# SLIMBUS1_DSP register map
Vendor: Texas Instruments
Peripheral module from a debugger description file (folder omap5430_ES2_PUBLIC).
Registers are 32-bit, access per field, reset 0x0 unless marked. A register's access mark holds for its fields unless they carry their own. Offsets are as the file gives them; lines under a group give offsets from that group; [hi:lo] are bit positions; {n}, {i} and the like mark numbered series; 'fields as' and 'values as' point back to an identical list; <NAME> marks a mode.

## SLIMBUS1_DSP
0x00 SLIMBUS_CMP_REVISION ro reset not defined — IP Revision Identifier Used by software to track features, bugs, and compatibility
  [31:0] REVISION — Revision Number
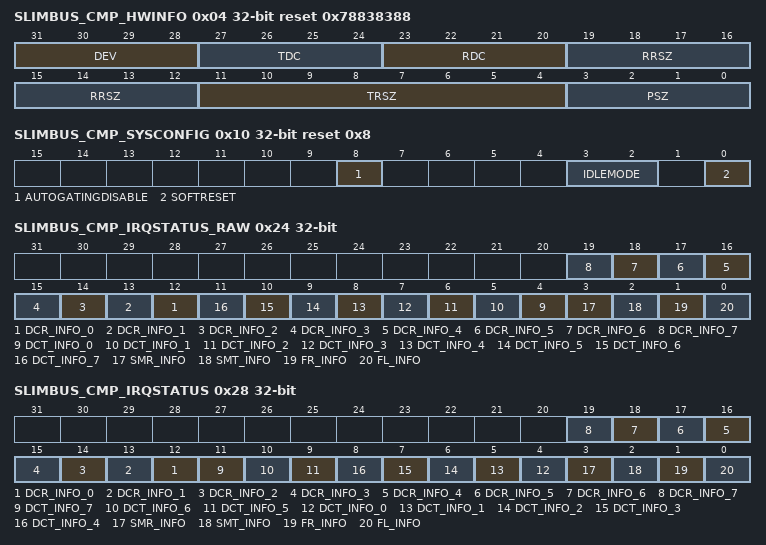
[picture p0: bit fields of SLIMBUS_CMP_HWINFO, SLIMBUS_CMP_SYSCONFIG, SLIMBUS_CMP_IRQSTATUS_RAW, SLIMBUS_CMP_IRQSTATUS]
0x04 SLIMBUS_CMP_HWINFO ro reset 0x78838388 — Those read-only, hardcoded fields display the values of the eponymous hardware configuration
  [31:28] DEV — Device count: number of devices supported by the component, most notably through the automatically reception of the messages addressed to them. Sets the number of instances of the 'DEV_XYZ' registers.
  [27:24] TDC — Transmit Data agent Count: Number of transmit hardware data agents (FIFO and associated logic) Sets the number of instances of the 'DCT_XYZ' registers.
  [23:20] RDC — Receive Data agent Count: Number of receive hardware data agents (FIFO and associated logic) Sets the number of instances of the 'DCR_XYZ' registers.
  [19:12] RRSZ — Size of receive FIFO RAM, in 32-bit words. RX message FIFO and all RX data FIFOs map to that shared RAM.
  [11:4] TRSZ — Size of transmit FIFO RAM, in 32-bit words. TX message FIFO and all TX data FIFOs map to that shared RAM.
  [3:0] PSZ — Size of (both TX and RX) FIFO segment word pointers, in bits. Determines the maximum number of (variable-sized) segment words a data agent FIFO can contain. Sets the width of FIFO control and status fields: size, threshold, level.
0x10 SLIMBUS_CMP_SYSCONFIG reset 0x8 — This register allows controlling various parameters of the interconnect interface
  [8] AUTOGATINGDISABLE rw — Control of the internal clock autogating for safety / debug only. No impact on module functionality, only on dynamic power.
    0=Internal clocks are gated off when unused, power is optimized; 1=Internal clocks are free-running, maximum dynamic power
  [3:2] IDLEMODE rw — Configuration of the local target state management mode. By definition, target can handle read/write transaction as long as it is out of IDLE state.
    0=IP_0 (Force-idle mode: local target's idle state follows (acknowledges) the system's idle requests unconditionally, that is, regardless of the IP module's internal requirements. Backup mode, for debug only.); 1=No-idle mode: local target never enters idle state. Backup mode, for debug only.; 2=IP_IP_(IRQ-_2 (Smart-idle mode: local target's idle state eventually follows (acknowledges) the system's idle requests, depending on the IP module's internal requirements. IP module shall not generate (IRQ- or DMA-request-related) wakeup events.); 3=IP_IP_(IRQ-_3 (Smart-idle wakeup-capable mode: local target's idle state eventually follows (acknowledges) the system's idle requests, depending on the IP module's internal requirements. IP module may generate (IRQ- or DMA-request-related) wakeup events when in idle state.)
  [0] SOFTRESET rw — Software reset. (Optional)
    0=No_action; 1=Initiate_software_reset; 1=Reset_(software_or_other)_ongoing; 0=Reset_done,_no_pending_action
0x24 SLIMBUS_CMP_IRQSTATUS_RAW access not given — Component (that is, main) interrupt request status. Check the corresponding secondary status register. Raw status is set even if event is not enabled. Write 1 to set the (raw) status, mostly for debug.
  [all] fields
    0=No_action; 1=Trigger_IRQ_event_by_software; 1=IRQ_event_pending; 0=No_event_pending
  [n+12] DCR_INFO_{n} (n=0..7) — IRQ status for RX Data agent {n} (access RW W1toSet)
  [n+4] DCT_INFO_{n} (n=0..7) — IRQ status for TX Data agent {n} (access RW W1toSet)
  [3] SMR_INFO — IRQ status for message receive (access RW W1toSet)
  [2] SMT_INFO — IRQ status for message transmit (access RW W1toSet)
  [1] FR_INFO — IRQ status for Framer device, when active (access RW W1toSet)
  [0] FL_INFO — IRQ status for Frame Layer (access RW W1toSet)
0x28 SLIMBUS_CMP_IRQSTATUS access not given — Component (that is, main) interrupt request status. Check the corresponding secondary status register. Enabled status isn't set unless event is enabled. Write 1 to clear the status after interrupt has been serviced (raw status gets cleared, that is, even if not enabled).
  [all] fields
    0=No_action; 1=Clear_pending_event,_if_any; 1=IRQ_event_pending; 0=No_event_pending
  [n+12] DCR_INFO_{n} (n=0..7) — IRQ status for RX Data agent {n} (access RW W1toClr)
  [11] DCT_INFO_7 — IRQ status for TX Data agent 7 (access RW W1toClr)
  [10] DCT_INFO_6 — IRQ status for TX Data agent 6 (access RW W1toClr)
  [9] DCT_INFO_5 — IRQ status for TX Data agent 5. (access RW W1toClr)
  [n+4] DCT_INFO_{n} (n=0..4) — IRQ status for TX Data agent {n} (access RW W1toClr)
  [3] SMR_INFO — IRQ status for message receive (access RW W1toClr)
  [2] SMT_INFO — IRQ status for message transmit (access RW W1toClr)
  [1] FR_INFO — IRQ status for Framer device, when active (access RW W1toClr)
  [0] FL_INFO — IRQ status for Frame Layer (access RW W1toClr)
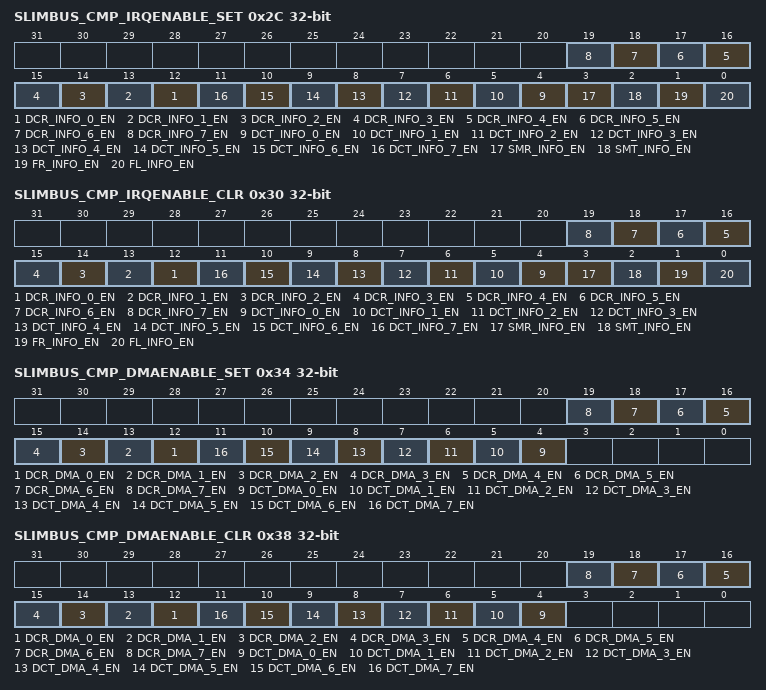
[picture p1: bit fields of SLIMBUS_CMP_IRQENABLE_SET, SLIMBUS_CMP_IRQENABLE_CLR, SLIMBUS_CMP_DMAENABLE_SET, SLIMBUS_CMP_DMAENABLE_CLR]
0x2C SLIMBUS_CMP_IRQENABLE_SET access not given — Component (that is, main) interrupt request enable Write 1 to set (enable interrupt). Readout equal to corresponding _CLR register.
  [all] fields
    0=No_action; 1=Set_IRQ_enable_(that_is,_enable_event); 1=IRQ_event_is_enabled; 0=IRQ_event_is_disabled
  [n+12] DCR_INFO_{n}_EN (n=0..7) — IRQ enable for RX Data agent {n} (access RW W1toSet)
  [n+4] DCT_INFO_{n}_EN (n=0..7) — IRQ enable for TX Data agent {n} (access RW W1toSet)
  [3] SMR_INFO_EN — IRQ enable for message receive (access RW W1toSet)
  [2] SMT_INFO_EN — IRQ enable for message transmit (access RW W1toSet)
  [1] FR_INFO_EN — IRQ enable for Framer device, when active (access RW W1toSet)
  [0] FL_INFO_EN — IRQ enable for Frame Layer (access RW W1toSet)
0x30 SLIMBUS_CMP_IRQENABLE_CLR access not given — Component (that is, main) interrupt request enable Write 1 to clear (disable interrupt). Readout equal to corresponding _SET register.
  [all] fields
    0=No_action; 1=IRQ_1 (Clear IRQ enable (that is, disable event)); 1=IRQ_event_is_enabled; 0=IRQ_event_is_disabled
  [n+12] DCR_INFO_{n}_EN (n=0..7) — IRQ enable for RX data agent {n} (access RW W1toClr)
  [n+4] DCT_INFO_{n}_EN (n=0..7) — IRQ enable for TX Data agent {n} (access RW W1toClr)
  [3] SMR_INFO_EN — IRQ enable for message receive (access RW W1toClr)
  [2] SMT_INFO_EN — IRQ enable for message transmit (access RW W1toClr)
  [1] FR_INFO_EN — IRQ enable for Framer device, when active (access RW W1toClr)
  [0] FL_INFO_EN — IRQ enable for Frame Layer (access RW W1toClr)
0x34 SLIMBUS_CMP_DMAENABLE_SET access not given — Components DMA enable (1 bit per DMA-capable channel) Write 1 to set (enable DMA). Readout equal to corresponding _CLR register.
  [all] fields
    0=No_action; 1=DMA_1 (Set DMA enable (that is, enable channel)); 1=DMA_channel_is_enabled; 0=DMA_chanel_is_disabled
  [n+12] DCR_DMA_{n}_EN (n=0..7) — DMA enable for RX Data agent {n} (access RW W1toSet.)
  [n+4] DCT_DMA_{n}_EN (n=0..7) — DMA enable for TX Data agent {n} (access RW W1toSet)
0x38 SLIMBUS_CMP_DMAENABLE_CLR access not given — Components DMA enable (1 bit per DMA-capable channel) Write 1 to clear (disable DMA). Readout equal to corresponding _SET register.
  [all] fields
    0=No_action; 1=DMA_1 (Clear DMA enable (that is, disable channel)); 1=DMA_channel_is_enabled; 0=DMA_chanel_is_disabled
  [n+12] DCR_DMA_{n}_EN (n=0..7) — DMA enable for RX Data agent {n} (access RW W1toClr)
  [n+4] DCT_DMA_{n}_EN (n=0..7) — DMA enable for TX Data agent {n} (access RW W1toClr)
0x40 SLIMBUS_CMP_IV — Component IV field, used as lower 8 bits of the devices' Enumeration Address (EA[47:0]). Identical for all devices of the component.
  [7:0] IV rw — Device component's Instance Value (IV[7:0])
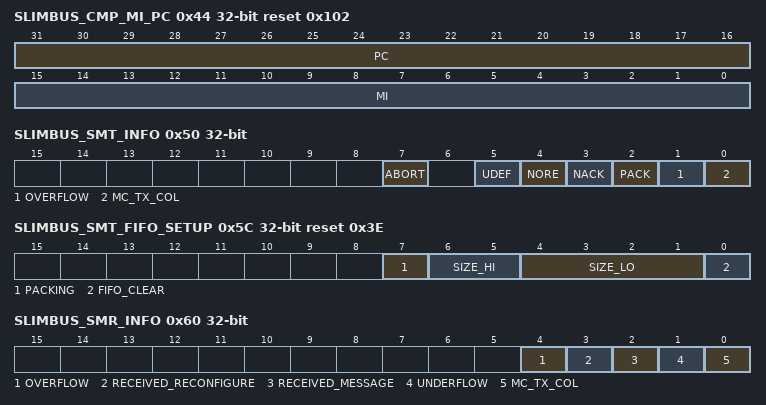
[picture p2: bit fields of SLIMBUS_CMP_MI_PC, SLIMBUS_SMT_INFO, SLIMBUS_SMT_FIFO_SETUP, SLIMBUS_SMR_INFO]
0x44 SLIMBUS_CMP_MI_PC rw reset 0x102 — Component MI and PC fields, used as upper 32 bits of the devices' Enumeration Address (EA[47:0]). Identical for all devices of the component.
  [31:16] PC — Device component's Product Code (PC[15:0])
  [15:0] MI — Device component's Manufacturer Index (MI[15:0])
0x50 SLIMBUS_SMT_INFO access not given — IRQ status for Shared Message Transmit channel. Write 1 to a bit to clear it.
  [all] fields
    values as the fields of SLIMBUS_CMP_IRQSTATUS
  [7] ABORT — TX message was aborted before completion because of message sync loss. (access RW W1toClr)
  [5] UDEF — TX message was UDEF'ed: undefined response, protocol error. (access RW W1toClr)
  [4] NORE — TX message was NORE'ed: no or all-zero message response (access RW W1toClr)
  [3] NACK — TX message was NACK'ed: at least one of the recipient devices requested message retransmission. (access RW W1toClr)
  [2] PACK — TX message was PACK'ed: all recipient devices accepted the message. (access RW W1toClr)
  [1] OVERFLOW — Overflow in TX message FIFO: Software tried to write more bytes than available in the FIFO. (access RW W1toClr)
  [0] MC_TX_COL — Transmit collision in Message Channel (MC) during message transmission. Interface device class-specific information element (IE) (access RW W1toClr)
0x54 SLIMBUS_SMT_MESSAGE rw — Shared Message Transmit FIFO input
  [31:0] TX_MESSAGE — TX message byte(s), depending on packing mode. Reads return 0. Enter the whole message except last byte (Message Integrity MI and Response MR), and with a don't care placeholder for Primary Integrity (PI).
0x58 SLIMBUS_SMT_CONTROL — Control of Shared Message channel Transmission.
  [0] MESSAGE_ENABLE rw — Enable the transmission of the message(s) previously written into the TX Message FIFO, with unlimited arbitration auto-retries. Self-cleared after either a message not get PACK'ed or the FIFO is empty.
    0=No_effect; 1=Request_transmission_of_stored_messages; 1=Message_transmission_is_ongoing; 0=MESSAGE_ENABLE_0_r (Message transmission is stopped / complete)
0x5C SLIMBUS_SMT_FIFO_SETUP reset 0x3E — Shared Message Transmit channel configuration. To be kept static during operation. Note that message segment word size is 2 slots = 1 byte (= message size granularity) and that message FIFO base address is always 0x0.
  [7] PACKING rw — Packing enable control for TX message FIFO
    0=Packing disabled: one byte per access only (LSByte), byte enable is don't care; 1=Packing enabled: one or several bytes per access, depending on byte enable
  [6:5] SIZE_HI rw — (Upper bits of the) capacity of shared TX message FIFO, in bytes, minus one. To be set for largest supported (transmitted) message(s).
    0=16_bytes_(minimum_size); 1=32_bytes_(recommended); 3=64_bytes_(max_size); 2=48_bytes_(large_messages)
  [4:1] SIZE_LO ro — (Lower bits of the) capacity of shared TX message FIFO, in bytes, minus one. Read-only, for reference only.
  [0] FIFO_CLEAR rw — Returns FIFO to initial empty state.
    0=No_effect; 1=Clear_FIFO; 1=FIFO_CLEAR_1_r (Ongoing Clear. Completion requires the SLIMbus clock.); 0=No_event,_last_clear_completed
0x60 SLIMBUS_SMR_INFO access not given — IRQ status for Shared Message Receive channel. Write 1 to a bit to clear it.
  [4] OVERFLOW — Overflow in RX message FIFO: received message is larger than the FIFO. (access RW W1toClr)
    0=no_action; 1=clear_event; 1=event_pending; 0=no_event_pending
  [3] RECEIVED_RECONFIGURE — RECONFIGURE_NOW message received, available in RX message FIFO (access RW W1toClr)
    values as OVERFLOW
  [2] RECEIVED_MESSAGE — Message available in the RX message FIFO. Clear bit to clear the FIFO and allow the reception of further messages (incoming messages will be NACK'ed until then). (access RW W1toClr)
    0=no_action; 1=FIFO,_1 (clear event, clear FIFO, allow further messages.); 1=event_pending; 0=no_event_pending
  [1] UNDERFLOW — Underflow in RX message FIFO: Software tried to read out more bytes than available. (access RW W1toClr)
    values as OVERFLOW
  [0] MC_TX_COL — Transmit collision in Message Channel (MC) during RX message during message reception. Interface device class-specific information element (IE) (access RW W1toClr)
    values as OVERFLOW
0x64 SLIMBUS_SMR_MESSAGE ro — Shared Message Receive channel FIFO output.
  [31:0] RX_MESSAGE — RX message byte(s), depending on packing mode. Writes have no effect. Readout value from an empty FIFO is undefined, that is, there is no defined 'reset value'. Message is guaranteed to have destination address matching a local device address (LA or EA), correct Primary and Message Integrity (PI and MI) and PACK Message Response (MR). Whole message available for readout, including the last byte (Message Integrity MI and Response MR)
0x68 SLIMBUS_SMR_CONTROL — Control of Shared Message channel Reception.
  [0] MESSAGE_DISABLE rw — Disables the reception of incoming messages (that is, broadcast or locally addressed) into the RX Message FIFO. Same effect for the same value than SMR_INFO[2] RECEIVED_MESSAGE, but this bit can be set to 1.
    0=Enabled: incoming messages will be PACK'ed; 1=Disabled: incoming messages will be NACK'ed
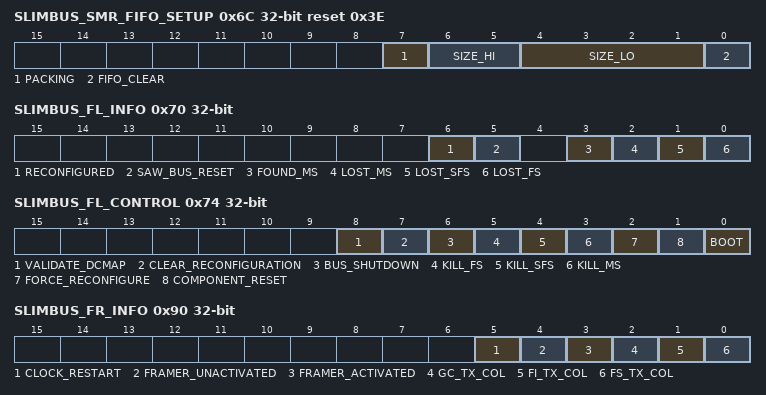
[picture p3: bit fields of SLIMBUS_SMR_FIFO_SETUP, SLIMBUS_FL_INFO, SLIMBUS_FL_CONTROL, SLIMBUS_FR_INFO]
0x6C SLIMBUS_SMR_FIFO_SETUP reset 0x3E — Shared Message Receive channel setup. To be kept static during operation. Note that message segment word size is 2 slots = 1 byte (= message size granularity) and that message FIFO base address is always 0x0.
  [7] PACKING rw — Packing enable control for RX message FIFO
    values as SLIMBUS_SMT_FIFO_SETUP.PACKING
  [6:5] SIZE_HI rw — (Upper bits of the) capacity of shared RX message FIFO, in bytes, minus one. To be set for largest supported (received) message.
    values as SLIMBUS_SMT_FIFO_SETUP.SIZE_HI
  [4:1] SIZE_LO ro — (Lower bits of the) capacity of shared RX message FIFO, in bytes, minus one. Read-only, for reference only.
  [0] FIFO_CLEAR rw — Returns message FIFO to initial empty state.
    values as SLIMBUS_SMT_FIFO_SETUP.FIFO_CLEAR
0x70 SLIMBUS_FL_INFO access not given — Frame Layer IRQ status. Write 1 to a bit to clear it. Note: FS loss implies SFS loss, and SFS loss implies MS loss, but only the 'strongest' loss event is logged for a given event.
  [all] fields
    values as the fields of SLIMBUS_CMP_IRQSTATUS
  [6] RECONFIGURED — Reconfiguration boundary crossed (access RW W1toClr)
  [5] SAW_BUS_RESET — Bus reset sequence detected on the bus: no activity on DATA line (all-zero) for 2 to 4 frames. Clock receiver FSM has returned to Reset state. Should trigger a local component reset (software sequence). (access RW W1toClr)
  [3] FOUND_MS — Message sync was acquired: operational state reached (access RW W1toClr)
  [2] LOST_MS — Message Synchronization was lost Interface device class-specific information element (IE) Note: Not asserted in case of FS or SFS loss. (access RW W1toClr)
  [1] LOST_SFS — Super Frame Synchronization was lost Interface device class-specific information element (IE) Note: Not asserted in case of FS loss. (access RW W1toClr)
  [0] LOST_FS — Frame Synchronization was lost Interface device class-specific information element (IE) (access RW W1toClr)
0x74 SLIMBUS_FL_CONTROL — Frame Layer control. (Self-cleared bits)
  [8] VALIDATE_DCMAP rw — Validates the mapping of data channels on devices: to be used after modifying the DC*_MAP* fields (DI and PN).
    0=No_action; 1=Validates_all_DCT_MAP_/_DCR_MAP_values
  [7] CLEAR_RECONFIGURATION rw — Clear all updates cumulated since the last reconfiguration, return reconfiguration fields to currently active value. Self-cleared immediately.
    0=No_action; 1=Clear_reconfiguration
  [6] BUS_SHUTDOWN rw — Sets both the clock source or the clock receiver FSMs back to 'Undefined' state at the next reconfiguration boundary. Executed (and bit self-cleared) on next reconfiguration (forced or not); also cleared by a 'clear_reconfiguration'.
    0=BUS_SHUTDOWN_0_w (Cancel pending request (not used in normal operation) if any, otherwise no action); 1=Assert_request_for_next_reconfiguration; 1=BUS_SHUTDOWN_1_r (Request pending for next reconfiguration); 0=BUS_SHUTDOWN_0_r (No request pending for next reconfiguration)
  [5] KILL_FS rw — Force immediate Frame Synchronization loss (implying as well message and superframe sync) When in 'Operational', 'SeekingMessageSync' or 'SeekingSuperFrameSync' states, component shall go to 'SeekingFrameSync' and start reaquiring frame sync. No effect otherwise. For debug use.
    0=No_action; 1=Force_frame_sync_loss; 0=KILL_FS_0_r (Always reads 0 because of immediate action.)
  [4] KILL_SFS rw — Force SuperFrame Synchronization loss at next reconfiguration boundary (implying as well message sync loss). When in 'Operational' or 'SeekingMessageSync' states, component shall go to 'SeekingSuperFrameSync' and start reaquiring superframe sync. No effect otherwise. Used by clock receiver component upon imcompletely received reconfiguration sequence.
    0=No_action; 1=Schedule_superframe_sync_loss; 1=Superframe_sync_loss_pending; 0=No_pending_superframe_sync_loss
  [3] KILL_MS rw — Force an immediate Message Synchronization loss. When in 'Operational' state, component shall go to 'SeekingMessageSync' and start reaquiring message sync. No effect otherwise. For debug use.
    0=No_action; 1=Force_message_sync_loss; 0=KILL_MS_0_r (Always reads 0 because of immediate action.)
  [2] FORCE_RECONFIGURE rw — Force a reconfiguration boundary at next superframe boundary, rather than wait for a RECONFIGURE_NOW() message.
    0=FORCE_RECONFIGURE_0_w (Cancel pending request (not used in normal operation) if any, otherwise no action); 1=FORCE_RECONFIGURE_1_w (Assert reconfiguration request for next superframe boundary); 1=FORCE_RECONFIGURE_1_r (Reconfiguration request pending for next superframe boundary); 0=No_request_pending
  [1] COMPONENT_RESET rw — Component reset request control: Transitions clock receiver FSM to state 'Reset' (from any other state). Immediate action. Set upon reception of the RESET_DEVICE() message by the interface device, which requires a component-level reset. Note that a component-level reset is also required in case of bus reset, but the transition to 'Reset' state happens automatically in that case and this bit is not used.
    1=Assert_request_for_next_reconfiguration
  [0] BOOT rw — Boot the component when not in active framer mode (don't care when in active framer mode). Transitions clock receiver FSM from state 'Undefined' to 'Reset'.
    0=No_action; 1=Enable_clock_receiver_boot_sequence
0x78 SLIMBUS_FL_SM — Subframe mode (SM: defines control vs. data space partition) control and status Software must write in values : a) to use when booting in active framer mode. b) extracted from NEXT_SUBFRAME_MODE(SM), to use at following reconfiguration boundary. Hardware-updated upon superframe sync acquisition, when booting in clock receiver mode.
  [4:0] SM rw — Subframe Mode, which sets Control Space Width (CSW) and Subframe Length (SFL), both expressed in slots. Note that we always have CSW ≤ SFL since the control is included in the subframe.
    13=CSW=3;_SFL=8_(37.5%_control); 21=CSW=6;_SFL=8_(75%_control); 30=reserved._Same_effect_than_0b00000; 8=CSW=2;_SFL=6_(33.3%_control); 5=CSW=1;_SFL=8_(12.5%_control); 27=CSW=12;_SFL=32_(37.5%_control); 2=reserved._Same_as_0x00; 4=CSW=1;_SFL=6_(16.7%_control); 6=CSW=1;_SFL=24_(4.17%_control); 1=reserved._Same_as_0x05; 29=CSW=16;_SFL=32_(50%_control); 0=CSW=8;_SFL=8_(100%_control_vs._0%_data); 11=CSW=2;_SFL=32_(6.25%_control); 3=reserved._Same_as_0x07; 23=CSW=6;_SFL=32_(18.8%_control); 17=CSW=4;_SFL=8_(50%_control); 10=CSW=2;_SFL=24_(8.33%_control); 9=CSW=2;_SFL=8_(25%_control); 16=CSW=4;_SFL=6_(66.7%_control); 18=CSW=4;_SFL=24_(16.7%_control); 19=CSW=4;_SFL=32_(12.5%_control); 24=CSW=8;_SFL=24_(33.3%_control); 20=reserved._Same_as_0x00; 14=CSW=3;_SFL=24_(12.5%_control); 22=CSW=6;_SFL=24_(25%_control); 28=CSW=16;_SFL=24_(66.7%_control); 7=CSW=1;_SFL=32_(3.13%_control); 25=CSW=8;_SFL=32_(25%_control); 31=CSW=24;_SFL=32_(75%_control); 26=CSW=12;_SFL=24_(50%_control); 15=CSW=3;_SFL=32_(9.38%_control); 12=CSW=3;_SFL=6_(50%_control)
0x7C SLIMBUS_FL_CG — Clock Gear (CG) control and status Software must write in values : a) to use when booting in active framer mode. b) extracted from NEXT_CLOCK_GEAR(CG), to use at following reconfiguration boundary. Hardware-updated upon superframe sync acquisition, when booting in clock receiver mode.
  [3:0] CG rw — Clock Gear (CG) to be used after the next reconfiguration boundary. Root / SLIMbus frequency ratio is defined as 2
    6=Ratio_to_root_frequency:_16; 1=Ratio_to_root_frequency:_512; 10=Ratio_to_root_frequency:_1_(undivided); 7=Ratio_to_root_frequency:_8; 3=Ratio_to_root_frequency:_128; 2=Ratio_to_root_frequency:_256; 8=Ratio_to_root_frequency:_4; 9=Ratio_to_root_frequency:_2; 5=Ratio_to_root_frequency:_32; 4=Ratio_to_root_frequency:_64
0x80 SLIMBUS_FL_RF — Root frequency (RF = SLIMbus clock frequency when in gear 10) control and status Software must write in values : a) to use when booting in active framer mode. b) extracted from NEXT_ROOT_FREQUENCY(RF), to use at following reconfiguration boundary. Hardware-updated upon superframe sync acquisition, when booting in clock receiver mode.
  [3:0] RF rw — Root frequency
    {v}={v+18}_MHz (v=6..9); 1=24.576_MHz; 0=Root_frequency_not_indicated; 2=22.5792_MHz; 4=16.8_MHz; 5=19.2_MHz; 3=15.36_MHz
0x90 SLIMBUS_FR_INFO access not given — Framer device status (when active). Write 1 to a bit to clear it.
  [all] fields
    0=no_event_pending; 1=event_pending
  [5] CLOCK_RESTART — Clock restart request event detected (that is, asynchronous DATA line transition during clock pause) (access RW W1toClr)
  [4] FRAMER_UNACTIVATED — Framer has left clock source operational state. Set on ACTIVE_FRAMER information element deassertion. (framer device class-specific IE) (access RW W1toClr)
  [3] FRAMER_ACTIVATED — Framer has reached clock source operational state. Set on ACTIVE_FRAMER information element assertion. (framer device class-specific IE) (access RW W1toClr)
  [2] GC_TX_COL — Collision during guide byte transmit (Guide Channel) Framer device class-specific information element (IE) (access RW W1toClr)
  [1] FI_TX_COL — Collision during Framing Information transmit (framing channel) Framer device class-specific information element (IE) (access RW W1toClr)
  [0] FS_TX_COL — Collision during Frame Sync symbol transmit (framing channel) Framer device class-specific information element (IE) (access RW W1toClr)
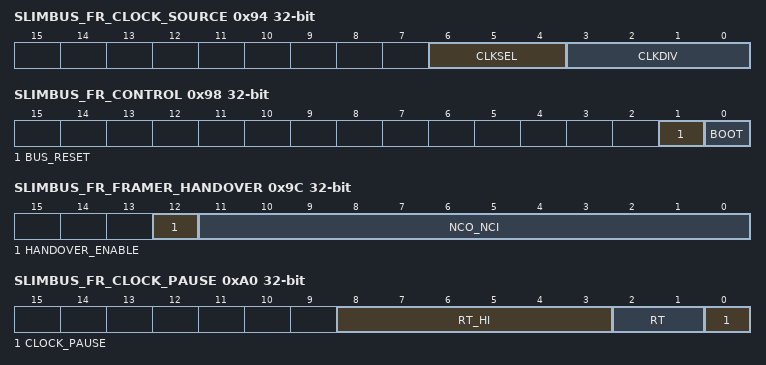
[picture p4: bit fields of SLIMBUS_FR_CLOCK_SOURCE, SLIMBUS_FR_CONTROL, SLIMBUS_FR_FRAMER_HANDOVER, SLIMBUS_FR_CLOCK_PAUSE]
0x94 SLIMBUS_FR_CLOCK_SOURCE — Root clock configuration for active framer mode, used at next reconfiguration boundary. Unused when not active framer.
  [6:4] CLKSEL rw — SLIMbus clock selection
    0=FCLK1; 1=FCLK2; 2=FCLK3
  [3:0] CLKDIV rw — Root divider ratio, applied on clock input to obtain root clock, to be used at next reconfiguration boundary. Input/ root frequency ratio is defined as 2 With CG the SLIMbus clock gear, Input / SLIMbus frequency ratio is therefore 2 WARNING: that last ratio has to be 1 or greater, to be implementable by the actual clock divider.
    6=Ratio_is_2; 1=Ratio_is_1/16:_Gears_7_to_10_forbidden; 10=Ratio_is_32; 7=Ratio_is_4; 0=Ratio_is_1/32:_Gears_6_to_10_forbidden; 2=Ratio_is_1/8:_Gears_8_to_10_forbidden; 8=Ratio_is_8; 9=Ratio_is_16; 4=Ratio_is_1/2:_Gear_10_forbidden; 5=Ratio_is_1_(root_freq._=_input_freq.); 3=Ratio_is_1/4:_Gears_9-10_forbidden
0x98 SLIMBUS_FR_CONTROL — Framer Device control. Unused when not active framer. (Self-cleared bits)
  [1] BUS_RESET rw — Bus reset request control, when framer is already active. Set upon reception of the NEXT_RESET_BUS() message. Transitions clock source FSM to state 'StartingClock' (from 'Operational').
    0=BUS_RESET_0_w (Cancel pending request (not used in normal operation) if any, otherwise no action); 1=Assert_request_for_next_reconfiguration; 1=BUS_RESET_1_r (Request pending for next reconfiguration); 0=BUS_RESET_0_r (No request pending for next reconfiguration)
  [0] BOOT rw — Initiate an active framer (clock source) boot sequence for the component, that is, when component is default active framer. Transitions clock source FSM from state 'Undefined' to 'CheckingDataLine'. Transitions clock receiver FSM from state 'Undefined' to 'Reset'. No effect if bus has already booted.
    0=BOOT_0_w (Cancel pending request (not used in normal operation) if any, otherwise no action); 1=Assert_request_for_next_reconfiguration; 1=BOOT_1_r (Request pending for next reconfiguration); 0=BOOT_0_r (No request pending for next reconfiguration)
0x9C SLIMBUS_FR_FRAMER_HANDOVER — Framer handover control (outgoing if currently active, incoming if currently inactive)
  [12] HANDOVER_ENABLE rw — Enable framer handover, upon NEXT_ACTIVE_FRAMER(NCi,NCo) reception. Self-cleared upon handover, that is, at next reconfiguration boundary.
    0=No_framer_handover; 1=Framer handover at next configuration boundary
  [11:0] NCO_NCI rw — NCo[11:0] / NCi[11:0] for outgoing / incoming framer respectively, as extracted from NEXT_ACTIVE_FRAMER(NCi,NCo) Used on framer handover at next reconfiguration boundary.
0xA0 SLIMBUS_FR_CLOCK_PAUSE — Clock and pause restart control. Applied at following reconfiguration boundary, that is, where the clock is paused. Note that programming is indentical for an active framer (clock source) and a clock receiver.
  [8:3] RT_HI ro — MSBs of 8-bit SLIMbus parameter. Constant.
    0=Only_legal,_unreserved_value
  [2:1] RT rw — Restart Time (RT) for recovery after clock pause, as extracted from NEXT_PAUSE_CLOCK(RT) LSBs of 8-bit SLIMbus parameter. Unused when not active framer.
    0=Fast_recovery_(less_than_4_cells); 1=Constant-phase recovery (superframe phase preserved); 2=Unspecified_recovery_delay
  [0] CLOCK_PAUSE rw — Control clock pause / restart. Self-cleared upon restart.
    0=Force clock restart if paused, no effect otherwise; 1=Pause clock (clock source) or expect clock pause (clock receiver) at next configuration boundary
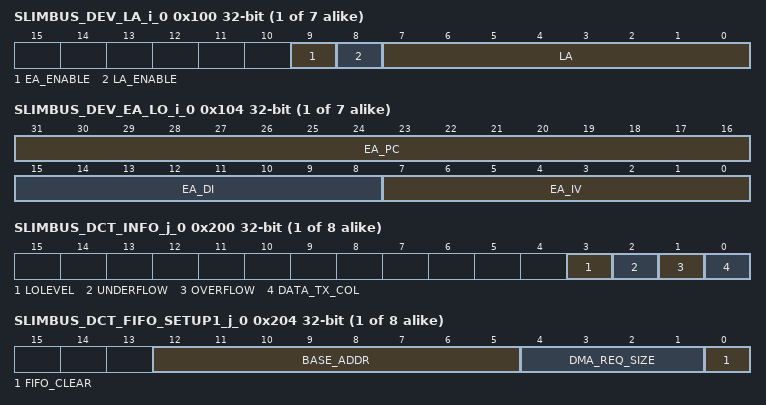
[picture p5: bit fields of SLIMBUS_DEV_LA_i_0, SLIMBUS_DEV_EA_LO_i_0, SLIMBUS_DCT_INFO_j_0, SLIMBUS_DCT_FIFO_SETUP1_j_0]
{0x100+0x10*i} SLIMBUS_DEV_LA_i_{i} (i=0..6) — Device Logical Address control
  [9] EA_ENABLE rw — Enables the reception of 'long-header' messages to the device's hardwired Enumeration Address (EA). Don't care if LA_ENABLE is 1.
    0=EA_is_not_valid; 1=EA_is_used_for_message_reception
  [8] LA_ENABLE rw — Enables the reception of 'short-header' messages to the device's Logical Address (LA).
    0=LA_is_not_valid; 1=LA_1 (LA valid, to be used for message reception)
  [7:0] LA rw — Device Logical Address, assigned by manager device at enumeration (0x00 through 0xEF). The active manager device itself has address 0xFF by default.
    255=active_manager_device_address
{0x104+0x10*i} SLIMBUS_DEV_EA_LO_i_{i} ro (i=0..6) — Device's Enumeration Address (EA[47:0]), lower 32 bits. For reference.
  [31:16] EA_PC — Product Code (PC[15:0]), shared by all devices of the component
  [15:8] EA_DI — Device Index (DI[15:0]), hardcoded from 0 upwards (0x00,0x01,0x02, etc...) each device of the component. WARNING: value is incorrectly given as 0x00 for all indexes.
  [7:0] EA_IV — Component's Instance Value (IV[7:0]), shared by all devices of the component
{0x108+0x10*i} SLIMBUS_DEV_EA_HI_i_{i} ro reset 0x102 (i=0..6) — Device's Enumeration Address (EA[47:0]), upper 16 bits. For reference.
  [15:0] EA_MI — Manufacturer Index (MI[15:0]), shared by all devices
{0x200+0x20*i} SLIMBUS_DCT_INFO_j_{i} access not given (i=0..7) — TX data agent status. Write 1 to a bit to clear it.
  [all] fields
    values as the fields of SLIMBUS_CMP_IRQSTATUS
  [3] LOLEVEL — Write level of TX data agent FIFO has gone above DMA threshold (that is, writes required to fill FIFO) Note: Defaults to 0 (even though FIFO is then empty) as it sets to 1 only when read-only status bit DCT_FIFO_STATUS.LOLEVEL transitions from 0 to 1, that is, when threshold is actually crossed downward. (access RW W1toClr)
  [2] UNDERFLOW — Underflow in TX data agent FIFO. Note: never asserted in pushed or async TPs, by construction. (access RW W1toClr)
  [1] OVERFLOW — Overflow in TX data agent FIFO. (access RW W1toClr)
  [0] DATA_TX_COL — TX collision in TX data agent. Core information element (IE). (access RW W1toClr)
{0x204+0x20*i} SLIMBUS_DCT_FIFO_SETUP1_j_{i} (i=0..7) — TX data agent FIFO setup. To be kept static during channel operation.
  [12:5] BASE_ADDR rw — TX data agent FIFO base address within shared TX RAM. (physical address of the 32-bit wide RAM array)
  [4:1] DMA_REQ_SIZE rw — DMA request size minus 1, in write accesses. In counting (packet) mode, last request may be smaller. Only applicable in precise DMA mode.
    15=16_accesses_per_DMA_request; 0=1_access_per_DMA_request
  [0] FIFO_CLEAR rw — Returns FIFO to initial empty state.
    values as SLIMBUS_SMT_FIFO_SETUP.FIFO_CLEAR
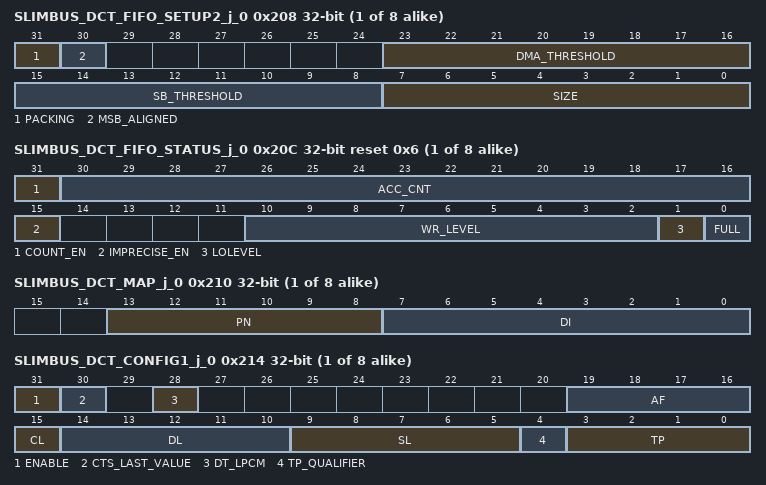
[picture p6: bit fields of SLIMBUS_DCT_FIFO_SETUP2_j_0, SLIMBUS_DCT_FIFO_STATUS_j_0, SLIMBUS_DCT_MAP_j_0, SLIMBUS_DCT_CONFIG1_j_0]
{0x208+0x20*i} SLIMBUS_DCT_FIFO_SETUP2_j_{i} (i=0..7) — TX data agent FIFO setup, continued. To be kept static during channel operation.
  [31] PACKING rw — Packing enable control
    0=Packing disabled: one segment word per write access. Byte enable is don't care.; 1=Packing enabled: one or several segment words per write access, depending on segment word size and byte enable. Only works in LSB-aligned mode. Behaviour in LSB-aligned mode is undefined.
  [30] MSB_ALIGNED rw — PLACEHOLDER, NO EFFECT: DATA ALWAYS LSB-aligned LSB/MSB-alignment of FIFO input (write) TX data.
    0=Input_data_is_LSB-aligned; 1=Input_data_is_MSB-aligned
  [23:16] DMA_THRESHOLD rw — SW-side TX data agent FIFO threshold. DMA write requests get (re-)asserted when WR_LEVEL is above threshold. Range: 0 to SIZE field value (included).
    255=DMA_FIFO_FIFO_255 (DMA writes requested whenever FIFO is empty (assuming maximum FIFO size)); 0=DMA_FIFO_0 (DMA writes requested whenever FIFO is not full)
  [15:8] SB_THRESHOLD rw — SLIMbus-side TX data agent FIFO threshold, used for SLIMbus transmission.
    255=FIFO_FIFO_255 (Threshold condition = FIFO is full (assuming maximum FIFO size)); 0=Threshold_condition_=_FIFO_is_not_empty
  [7:0] SIZE rw — Capacity of FIFO in segment words, minus one.
    255=Maximum_FIFO_size; 0=FIFO_is_1-word_deep_(not_recommended); 3=FIFO_3 (FIFO is 4-word deep. Recommended minimum setting (SLIMbus protocol).)
{0x20C+0x20*i} SLIMBUS_DCT_FIFO_STATUS_j_{i} reset 0x6 (i=0..7) — TX data agent FIFO status, for software (non-DMA) FIFO management.
  [31] COUNT_EN rw — Down-counter mode control. Only applicable in precise DMA mode.
    0=ACC_CNT_ACC_CNT_DMA_0 (Disable down-counter mode. Should typically be used only when ACC_CNT = 0. If ACC_CNT > 0, DMA request gets deasserted immediately.); 1=ACC_CNT_1 (Enable down-counter mode. ACC_CNT is typically set to the desired value in the same write access.); 1=DMA_ACC_CNT_1 (Down-counter mode is enabled. DMA request can only be active when ACC_CNT > 0); 0=DMA_FIFO_0 (Down-counter mode is disabled: DMA request follows FIFO level, and is active during no-tx periods.)
  [30:16] ACC_CNT rw — 'Packet mode' down-counter of segment words, decremented on DCT_DATA write accesses. In that mode, DMA request shall deassert when ACC_CNT = 0 (that is, packet fully transmitted / stored in TX FIFO).
    0=DMA_0 (Deasserts current DMA request by forcing the count to zero (not typical operation)); 127=DMA_127 (Set largest packet size (in accesses) to transfer before DMA request deassertion. Any lower value is also valid to enter.); 127=DMA_127 (Maximum number of accesses still to be transferred before DMA deassertion. Unless interrupted, counter shall go through all values down to zero.); 0=DMA_0 (No access left to transfer, DMA request currently inactive.)
  [15] IMPRECISE_EN rw — Precise vs. Imprecise DMA requesting mode control. (A DMA request is a single assertion-deassertion cycle.)
    0=DMA_0 (DMA request contains a precise number of accesses); 1=DMA_1 (DMA request is not expected to trigger a fixed number of accesses)
  [10:2] WR_LEVEL ro — Number of free segment words in FIFO, that could be filled by writes.
    0x100=FIFO_FIFO_256 (FIFO is empty and entirely available for writes (assuming maximum FIFO size)); 0=FIFO_is_full_and_cannot_be_written_to
  [1] LOLEVEL ro — Indicator of write level (WR_LEVEL: number of free words in FIFO) with respect to (write) threshold (DMA_threshold). Activates DMA write requests when high.
    1=WR_LEVEL_>_DMA_THRESHOLD; 0=WR_LEVEL_≤_DMA_THRESHOLD
  [0] FULL ro — FIFO full indicator
    1=FIFO_(WR_LEVEL_1 (no space left in FIFO to write a word (WR_LEVEL = 0)); 0=FIFO_(WR_LEVEL_0 (some space left in FIFO to write at least one word (WR_LEVEL > 0))
{0x210+0x20*i} SLIMBUS_DCT_MAP_j_{i} (i=0..7) — Associates a device and port to the TX data agent. Write to field FL_CONTROL.validate_dcmap to validate changes.
  [13:8] PN rw — Port Number (PN), identifies the data channel's port for the device. Shall be unique within a device. Note that a half-duplex (bidirectional) port has 2 data agents with the same PN, 1 TX + 1 Rx.
  [7:0] DI rw — Index (DI) of the device this data agent belongs to. Devices are hard-indexed from 0 upwards.
{0x214+0x20*i} SLIMBUS_DCT_CONFIG1_j_{i} (i=0..7) — TX data agent configuration, applied at the next reconfiguration boundary
  [31] ENABLE rw — Data agent enabling control. Auto-cleared upon frame or superframe sync loss.
    1=Data_agent_is_enabled; 0=Data_agent_is_disabled
  [30] CTS_LAST_VALUE ro — Last received value of the CTS TAG bit. Only updated for asynchronous TP, when primary owner (that is, transmitter) of the channel.
    1=TAG.CTS=1_1 (Local sink signals TAG.CTS=1 that is, it can receive data (and remote source can transmit some)); 0=TAG.CTS=0_0 (Local sink signals TAG.CTS=0 that is, it cannot receive any data (and remote source shall not transmit any))
  [28] DT_LPCM rw — Unsigned-to-OSAM encoding enable for Data Type (DT) = LPCM audio (0x1)
    0=DT!=0x1:_encoding_disabled; 1=DT=0x1:_encoding_enabled
  [19:16] AF rw — Auxillairy Format (AF) used in segment word size calculation. Non-zero values not supported in extended asynchronous TPs.
    15=AUX_AUX_15 (User-defined 8-bit AUX (2 AUX slot per segment)); 0=AUX_AUX_0 (No AUX information (0 AUX slots per segment)); 1=ZCUV_IEC60958_AUX_1 (ZCUV for tunneling IEC60958 (1 AUX slot per segment)); 11=AUX_AUX_11 (User-defined 4-bit AUX (1 AUX slot per segment))
  [15] CL rw — Channel Link (CL) enable: Pairing up of current channel with previous one (that is, channel index below) Tied-0, read-only field for channel index 0, since there is no 'previous' channel in that case. TP and segment interval (encoded in SD) must be equal between the linked channels.
    0=Current channel independent from previous one; 1=Current channel paired up with previous one
  [14:10] DL rw — Segment Data Length (DL), in 4-bit slots (except when 0). AUX + DATA length shall fit in a segment word, that is, 1 to 32 bits. In extended async TPs, sets segment word size (0 and odd values illegal) instead.
    6=6_slots_(24_bits); 1=1_slot_(4_bits); 7=AUX_7 (7 slots (28 bits), requiring at most 1 AUX slot to fit in max-size 32-bit segment word); 0=TAG_AUX_DATA_0 (Length not indicated: Segment slots that are not TAG or AUX are DATA (that is, no unused slot)); 2=2_slots_(8_bits); 8=AUX_8 (8 slots (32 bits), requiring zero AUX slot, to fit in a max-size 32-bit segment word); 4=4_slots_(16_bits); 5=5_slots_(20_bits); 3=3_slots_(12_bits)
  [9:5] SL rw — total Segment Length (SL), in 4-bit slots. SL ≥ TAG length + AUX length + DATA length
    0=Reseved_value
  [4] TP_QUALIFIER rw — Qualifier for plain/extended half-duplex asynchronous TPs (owner ID). Unused and don't care for other TPs.
    0=T1_0 (1/2 duplex TPs: Local device is primary channel owner, uses T1 token); 1=T2_1 (1/2 duplex TPs: Local device is secondary channel owner, uses T2 token)
  [3:0] TP rw — Transport Protocol (TP) Determines also the TAG length (from 0 to 2 slots).
    6=TAG)_6 (Extended asynchronous-half-duplex (unicast, 2-slot TAG)); 1=Pushed_(multicast,_1-slot_TAG); 7=TAG)_7 (Extended asynchronous-simplex (unicast, 2-slot TAG)); 0=Isochronous_(multicast,_no_TAG); 2=Pulled_(unicast,_1-slot_TAG); 4=TAG)_4 (Asynchronous-simplex (unicast, 1-slot TAG)); 5=TAG)_5 (Asynchronous-half-duplex (unicast, 1-slot TAG)); 15=NOT_SUPPORTED,_RESERVED_VALUE_15 (User-defined protocol 2 NOT SUPPORTED, RESERVED VALUE); 3=TAG)_NOT_SUPPORTED,_RESERVED_VALUE_3 (Locked (multicast, no TAG) NOT SUPPORTED, RESERVED VALUE); 14=NOT_SUPPORTED,_RESERVED_VALUE_14 (User-defined protocol 1 NOT SUPPORTED, RESERVED VALUE)
{0x218+0x20*i} SLIMBUS_DCT_CONFIG2_j_{i} (i=0..7) — TX data agent configuration (continued), applied at the next reconfiguration boundary
  [11:0] SD rw — Segment Distribution (see)
{0x21C+0x20*i} SLIMBUS_DCT_DATA_j_{i} rw (i=0..7) — TX data agent DATA FIFO input. Reads have no effect on FIFO.
  [31:0] DATA — Data segment word, single-word or packed, LSB or MSB-aligned.
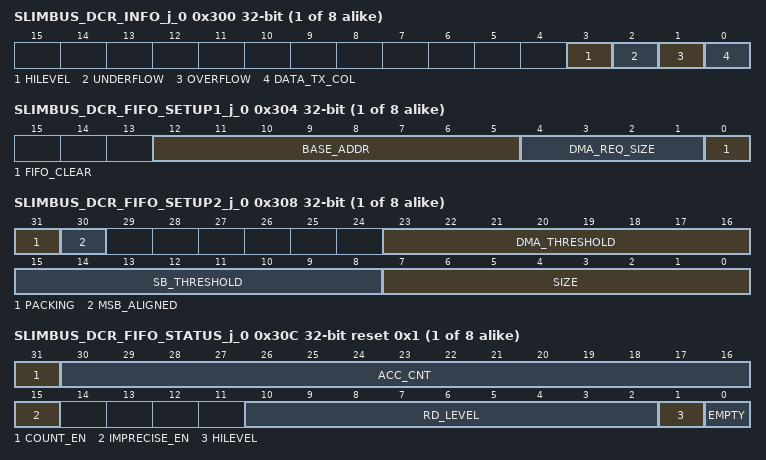
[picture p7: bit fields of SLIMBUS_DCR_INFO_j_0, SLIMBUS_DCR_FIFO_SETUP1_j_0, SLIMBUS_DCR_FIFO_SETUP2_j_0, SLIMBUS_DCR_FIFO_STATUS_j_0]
{0x300+0x20*i} SLIMBUS_DCR_INFO_j_{i} access not given (i=0..7) — RX data agent status. Write 1 to a bit to clear it.
  [all] fields
    values as the fields of SLIMBUS_CMP_IRQSTATUS
  [3] HILEVEL — Read level of RX data agent FIFO has gone above DMA threshold (that is, reads required to empty FIFO) (access RW W1toClr)
  [2] UNDERFLOW — Underflow in RX data agent FIFO (access RW W1toClr)
  [1] OVERFLOW — Overflow in RX data agent FIFO Note: never asserted in pulled or async TPs, by construction. (access RW W1toClr)
  [0] DATA_TX_COL — TX collision in RX data agent. Core information element (IE). (access RW W1toClr)
{0x304+0x20*i} SLIMBUS_DCR_FIFO_SETUP1_j_{i} (i=0..7) — RX data agent FIFO setup. To be kept static during channel operation.
  [12:5] BASE_ADDR rw — RX data agent FIFO base address within shared RX RAM. (physical address of the 32-bit wide RAM array)
  [4:1] DMA_REQ_SIZE rw — DMA request size minus 1, in read accesses. In counting (packet) mode, last request may be smaller. Only applicable in precise DMA mode.
    15=16_accesses_per_DMA_request; 0=1_access_per_DMA_request
  [0] FIFO_CLEAR rw — Returns FIFO to initial empty state.
    values as SLIMBUS_SMT_FIFO_SETUP.FIFO_CLEAR
{0x308+0x20*i} SLIMBUS_DCR_FIFO_SETUP2_j_{i} (i=0..7) — RX data agent FIFO setup, continued. To be kept static during channel operation.
  [31] PACKING rw — Packing enable control
    0=Packing disabled: one segment word per read access. Byte enable is don't care.; 1=Packing enabled: one or several segment words per read access, depending on segment word size and byte enable. Only works in LSB-aligned mode. Behaviour in LSB-aligned mode is undefined.
  [30] MSB_ALIGNED rw — PLACEHOLDER, NO EFFECT: DATA ALWAYS LSB-aligned LSB/MSB-alignment of FIFO output (read) RX data.
    0=Output_data_is_LSB-aligned; 1=Output_data_is_MSB-aligned
  [23:16] DMA_THRESHOLD rw — SW-side RX data agent FIFO threshold. DMA read requests get (re-)asserted when RD_LEVEL is above threshold. Range: 0 to SIZE field value (included).
    255=DMA_FIFO_FIFO_255 (DMA reads requested whenever FIFO is full (assuming maximum FIFO size)); 0=DMA_FIFO_0 (DMA reads requested whenever FIFO is not empty)
  [15:8] SB_THRESHOLD rw — SLIMbus-side RX data agent FIFO threshold, used for SLIMbus reception.
    values as SLIMBUS_DCT_FIFO_SETUP2_j_0.SB_THRESHOLD
  [7:0] SIZE rw — Capacity of FIFO in segment words, minus one.
    values as SLIMBUS_DCT_FIFO_SETUP2_j_0.SIZE
{0x30C+0x20*i} SLIMBUS_DCR_FIFO_STATUS_j_{i} reset 0x1 (i=0..7) — RX data agent FIFO status, for software (non-DMA) FIFO management.
  [31] COUNT_EN rw — Down-counter mode control. Only applicable in precise DMA mode.
    0=ACC_CNT_ACC_CNT_DMA_0 (Disable down-counter mode. Should typically be used only when ACC_CNT = 0. If ACC_CNT > 0, DMA request gets deasserted immediately.); 1=ACC_CNT_1 (Enable down-counter mode. ACC_CNT is typically set to the desired value in the same write access.); 1=DMA_ACC_CNT_1 (Down-counter mode is enabled: DMA request can only be active when ACC_CNT > 0); 0=DMA_FIFO_0 (Down-counter mode is disabled: DMA request follows FIFO level, and is active during no-transmission periods.)
  [30:16] ACC_CNT rw — 'Packet mode' down-counter of segment words, decremented on DCR_DATA read accesses. In that mode, DMA request shall reassert when ACC_CNT = RD_LEVEL (that is, whole packet received).
    values as SLIMBUS_DCT_FIFO_STATUS_j_0.ACC_CNT
  [15] IMPRECISE_EN rw — Precise vs. Imprecise DMA requesting mode control. (A DMA request is a single assertion-deassertion cycle.)
    0=DMA_0 (DMA request contains a defined number of accesses); 1=DMA_1 (DMA request is not expected to trigger a fixed number of accesses)
  [10:2] RD_LEVEL ro — Number of segment words stored in FIFO, that can be read out.
    0x100=FIFO_256 (FIFO is full of readable words (assuming maximum size)); 0=FIFO_contains_no_readable_word
  [1] HILEVEL ro — Indicator of read level (RD_LEVEL: number of readable segment words) with respect to (read) threshold (DMA_THRESHOLD). Activates DMA read requests when high.
    1=RD_LEVEL_>_DMA_THRESHOLD; 0=RD_LEVEL_≤_DMA_THRESHOLD
  [0] EMPTY ro — FIFO empty indicator
    1=FIFO_(RD_LEVEL_1 (FIFO contains no readable word (RD_LEVEL = 0)); 0=FIFO_(RD_LEVEL_0 (FIFO contains at least one readable word (RD_LEVEL > 0))
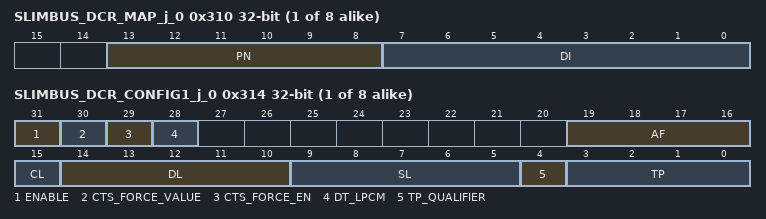
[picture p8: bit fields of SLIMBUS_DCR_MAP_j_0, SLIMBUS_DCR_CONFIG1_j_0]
{0x310+0x20*i} SLIMBUS_DCR_MAP_j_{i} (i=0..7) — Associates a device and port to the RX data agent. Write to field FL_CONTROL[8] VALIDATE_DCMAP to validate changes.
  fields as SLIMBUS_DCT_MAP_j_0
{0x314+0x20*i} SLIMBUS_DCR_CONFIG1_j_{i} (i=0..7) — RX data agent configuration, applied at the next reconfiguration boundary
  [31] ENABLE rw — Data agent enabling control. Auto-cleared upon frame or superframe sync loss.
    0=Data_agent_is_disabled; 1=Data_agent_is_enabled
  [30] CTS_FORCE_VALUE rw — Value to force the CTS TAG bit value when in asynchronous TP and secondary channel owner (that is, receiver) and CTS is forced (CTS_force_en=1) Don't care in all other cases. Warning: forcing CTS=1 can result in a FIFO overflow.
    0=TAG.CTS=0_0 (Local sink signals TAG.CTS=0 that is, it cannot receive any data (and remote source shall not transmit any)); 1=TAG.CTS=1_1 (Local sink signals TAG.CTS=1 that is, it can receive data (and remote source can transmit some))
  [29] CTS_FORCE_EN rw — Forces the CTS TAG bit value when in an asynchronous TP and secondary owner (that is, receiver) of the channel. Don't care in other cases.
    0=CTS_RX_FIFO_0 (CTS bit generated according to RX FIFO level); 1=CTS_bit_forced_to_CTS_force_value
  [28] DT_LPCM rw — OSAM-to-unsigned decoding enable for Data Type (DT) = LPCM audio (0x1)
    0=DT!=0x1:_decoding_disabled; 1=DT=0x1:_decoding_enabled
  [19:16] AF rw — Auxillairy Format (AF) used in segment word size calculation. Non-zero values not supported in extended asynchronous TPs.
    values as SLIMBUS_DCT_CONFIG1_j_0.AF
  [15] CL rw — Channel Link (CL) enable: Pairing up of current channel with previous one (that is, channel index below) Channel index 0 should have CL=0, since there is no 'previous' channel in that case. TP and segment interval (encoded in SD) must be equal between the linked channels.
    values as SLIMBUS_DCT_CONFIG1_j_0.CL
  [14:10] DL rw — Segment Data Length (DL), in 4-bit slots (except when 0). AUX + DATA length shall fit in a segment word, that is, 1 to 32 bits. In extended async TPs, sets segment word size (0 and odd values illegal) instead.
    values as SLIMBUS_DCT_CONFIG1_j_0.DL
  [9:5] SL rw — total Segment Length (SL), in 4-bit slots. SL ≥ TAG length + AUX length + DATA length
    0=Reseved_value
  [4] TP_QUALIFIER rw — Qualifier for plain/extended half-duplex asynchronous TPs (owner ID). Unused and don't care for other TPs
    values as SLIMBUS_DCT_CONFIG1_j_0.TP_QUALIFIER
  [3:0] TP rw — Transport Protocol (TP) Determines also the TAG length (from 0 to 2 slots).
    values as SLIMBUS_DCT_CONFIG1_j_0.TP
{0x318+0x20*i} SLIMBUS_DCR_CONFIG2_j_{i} (i=0..7) — RX data agent configuration (continued), applied at the next reconfiguration boundary
  [11:0] SD rw — Segment Distribution
{0x31C+0x20*i} SLIMBUS_DCR_DATA_j_{i} ro (i=0..7) — RX data agent DATA FIFO output. Writes have no effect on FIFO.
  fields as SLIMBUS_DCT_DATA_j_0
